# AVR32EB14 register map
Vendor: Atmel; File version: 1.0
CPU: other r0p0, little endian, no MPU, no FPU, 4 interrupt priority bits
Registers are 8-bit, read-write, reset 0x0 unless marked. A register's access mark holds for its fields unless they carry their own. Offsets are from the block's base; [hi:lo] are bit positions; {n}, {i} and the like mark numbered series; 'fields as' and 'values as' point back to an identical list.

## TCE0 — 16-bit Timer/Counter Type E
Base 0x00800A00
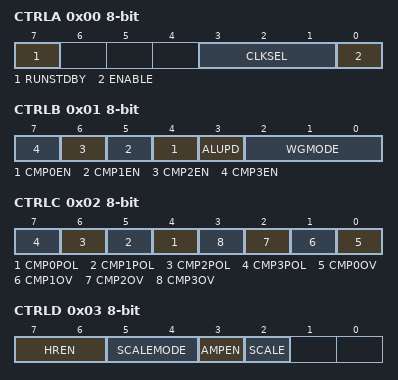
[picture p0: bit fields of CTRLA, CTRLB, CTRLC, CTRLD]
0x00 CTRLA — Control A
  [7] RUNSTDBY — Run in Standby
  [3:1] CLKSEL — Clock Selection
    0=DIV1 (System Clock); 1=DIV2 (System Clock / 2); 2=DIV4 (System Clock / 4); 3=DIV8 (System Clock / 8); 4=DIV16 (System Clock / 16); 5=DIV64 (System Clock / 64); 6=DIV256 (System Clock / 256); 7=DIV1024 (System Clock / 1024)
  [0] ENABLE — Module Enable
0x01 CTRLB — Control B
  [n+4] CMP{n}EN (n=0..3) — Compare {n} Enable
  [3] ALUPD — Auto Lock Update
  [2:0] WGMODE — Waveform generation mode
    0=NORMAL (Normal Mode); 1=FRQ (Frequency Generation Mode); 3=SINGLESLOPE (Single Slope PWM); 5=DSTOP (Dual Slope PWM, overflow on TOP); 6=DSBOTH (Dual Slope PWM, overflow on TOP and BOTTOM); 7=DSBOTTOM (Dual Slope PWM, overflow on BOTTOM)
0x02 CTRLC — Control C
  [n+4] CMP{n}POL (n=0..3) — Compare {n} Polarity
  [n] CMP{n}OV (n=0..3) — Compare {n} Waveform Output Value
0x03 CTRLD — Control D
  [7:6] HREN — High Resolution Enable
    0=OFF (High Resolution Disable); 1=4X (Resolution increased by 4 (2 bits)); 2=8X (Resolution increased by 4 (3 bits))
  [5:4] SCALEMODE — Scaling Mode
    0=CENTER (CMPn registers scaled vs center (50% duty cycle)); 1=BOTTOM (CMPn registers scaled vs BOTTOM (0% duty cycle)); 2=TOP (CMPn registers scaled vs TOP (100% duty cycle)); 3=TOPBOTTOM (CMPn registers scaled vs TOP or BOTTOM depending on written value.)
  [3] AMPEN — Amplitude Control Enable
  [2] SCALE — Scaled Write
    0=NORMAL (Absolute values used when writing to CMPn, CMPnBUF and registers); 1=FRACTIONAL (Fractional values used when writing to CMPn, CMPnBUF and registers)
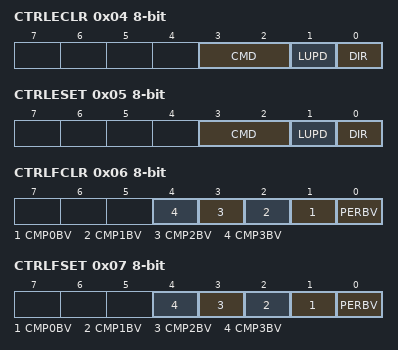
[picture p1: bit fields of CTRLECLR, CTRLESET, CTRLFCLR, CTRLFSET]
0x04 CTRLECLR — Control E Clear
  [3:2] CMD — Command
    0=NONE (No Command); 1=UPDATE (Force Update); 2=RESTART (Force Restart); 3=RESET (Force Hard Reset)
  [1] LUPD — Lock Update
  [0] DIR — Direction
0x05 CTRLESET — Control E Set
  [3:2] CMD — Command
    values as CTRLECLR.CMD
  [1] LUPD — Lock Update
  [0] DIR — Direction
    0=UP (Count up); 1=DOWN (Count down)
0x06 CTRLFCLR — Control F Clear
  [n+1] CMP{n}BV (n=0..3) — Compare {n} Buffer Valid
  [0] PERBV — Period Buffer Valid
0x07 CTRLFSET — Control F Set
  fields as CTRLFCLR
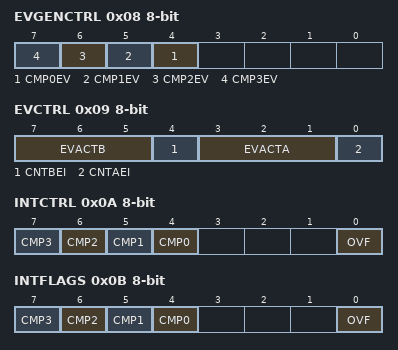
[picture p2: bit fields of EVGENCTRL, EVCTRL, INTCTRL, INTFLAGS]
0x08 EVGENCTRL — Event Generation Control
  [all] fields
    0=PULSE (Event output for CMP is a pulse); 1=WAVEFORM (Event output for CMP is equal to waveform)
  [n+4] CMP{n}EV (n=0..3) — Compare {n} Event
0x09 EVCTRL — Event Control
  [7:5] EVACTB — Event Action B
    0=NONE (No Action); 3=UPDOWN (Count on prescaled clock. Event controls count direction. Up-count when event line is 0, down-count when event line is 1.); 4=RESTART_POSEDGE (Restart counter at positive edge event); 5=RESTART_ANYEDGE (Restart counter on any edge event); 6=RESTART_HIGHLVL (Restart counter while event line is 1.)
  [4] CNTBEI — Count on Event Input B
  [3:1] EVACTA — Event Action A
    0=CNT_POSEDGE (Count on positive edge event); 1=CNT_ANYEDGE (Count on any edge event); 2=CNT_HIGHLVL (Count on prescaled clock while event line is 1.); 3=UPDOWN (Count on prescaled clock. Event controls count direction. Up-count when event line is 0, down-count when event line is 1.)
  [0] CNTAEI — Count on Event Input A
0x0A INTCTRL — Interrupt Control
  [n+4] CMP{n} (n=0..3) — Compare {n} Interrupt Enable
  [0] OVF — Overflow Interrupt Enable
0x0B INTFLAGS — Interrupt Flags
  [n+4] CMP{n} (n=0..3) — Compare {n} Interrupt Flag
  [0] OVF — Overflow Interrupt Flag
0x0E DBGCTRL — Debug Control
  [0] DBGRUN — Debug Run
0x0F TEMP — Temporary data for 16-bit Access
0x20 CNT 16-bit (reset mask 0xFF) — Count
0x22 AMP 16-bit (reset mask 0xFF) — Amplitude
0x24 OFFSET 16-bit (reset mask 0xFF)
0x26 PER 16-bit (reset mask 0xFF) — Period
{0x28+2i} CMP{i} 16-bit (reset mask 0xFF) (i=0..3) — Compare {i}
0x36 PERBUF 16-bit (reset mask 0xFF) — Period Buffer
{0x38+2i} CMP{i}BUF 16-bit (reset mask 0xFF) (i=0..3) — Compare {i} Buffer
